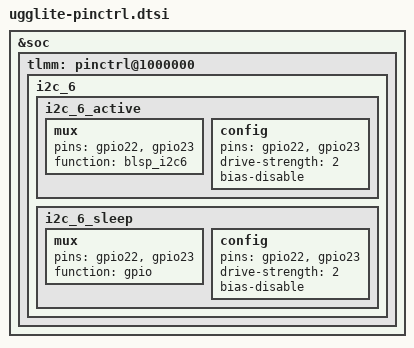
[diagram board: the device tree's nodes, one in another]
/*
 * Copyright (c) 2015-2016, The Linux Foundation. All rights reserved.
 * Copyright (C) 2018 XiaoMi, Inc.
 *
 * This program is free software; you can redistribute it and/or modify
 * it under the terms of the GNU General Public License version 2 and
 * only version 2 as published by the Free Software Foundation.
 *
 * This program is distributed in the hope that it will be useful,
 * but WITHOUT ANY WARRANTY; without even the implied warranty of
 * MERCHANTABILITY or FITNESS FOR A PARTICULAR PURPOSE.  See the
 * GNU General Public License for more details.
 */
&soc {
	tlmm: pinctrl@1000000 {
		i2c_6 {
			i2c_6_active: i2c_6_active {
				mux {
					pins = "gpio22", "gpio23";
					function = "blsp_i2c6";
				};

				config {
					pins = "gpio22", "gpio23";
					drive-strength = <2>;
					bias-disable;
				};
			};

			i2c_6_sleep: i2c_6_sleep {
				mux {
					pins = "gpio22", "gpio23";
					function = "gpio";
				};

				config {
					pins = "gpio22", "gpio23";
					drive-strength = <2>;
					bias-disable;
				};
			};
		};
	};
};
